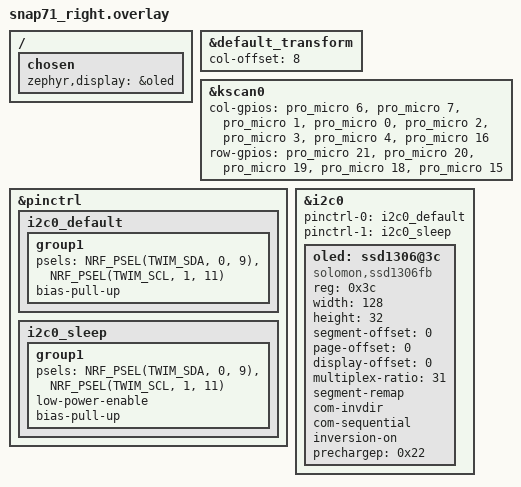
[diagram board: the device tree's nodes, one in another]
#include "snap71.dtsi"

/ {
    chosen {
    zephyr,display = &oled;
    };
};
&default_transform {
    // Set this to the number of columns on the left side.
    col-offset = <8>;
};

&kscan0 {
    // Replace these comments with the GPIO pins in the matrix for the right side.
    // See https://zmk.dev/docs/development/hardware-integration/new-shield#shield-overlays
    col-gpios
        = <&pro_micro 6 GPIO_ACTIVE_HIGH>
        , <&pro_micro 7 GPIO_ACTIVE_HIGH>
        , <&pro_micro 1 GPIO_ACTIVE_HIGH>
        , <&pro_micro 0 GPIO_ACTIVE_HIGH>
        , <&pro_micro 2 GPIO_ACTIVE_HIGH>
        , <&pro_micro 3 GPIO_ACTIVE_HIGH>
        , <&pro_micro 4 GPIO_ACTIVE_HIGH>
        , <&pro_micro 16 GPIO_ACTIVE_HIGH>
        ;
    row-gpios
        = <&pro_micro 21 (GPIO_ACTIVE_HIGH | GPIO_PULL_DOWN)>
        , <&pro_micro 20 (GPIO_ACTIVE_HIGH | GPIO_PULL_DOWN)>
        , <&pro_micro 19 (GPIO_ACTIVE_HIGH | GPIO_PULL_DOWN)>
        , <&pro_micro 18 (GPIO_ACTIVE_HIGH | GPIO_PULL_DOWN)>
        , <&pro_micro 15 (GPIO_ACTIVE_HIGH | GPIO_PULL_DOWN)>
        ;
};

&pinctrl {
    i2c0_default: i2c0_default {
        group1 {
            psels = <NRF_PSEL(TWIM_SDA, 0, 9)>,  /* Pro Micro Pin 7 / D7 -> P1.06 */
                    <NRF_PSEL(TWIM_SCL, 1, 11)>;   /* Pro Micro Pin 9 / D9 -> P0.11 */
                    bias-pull-up;  /* Add this - I2C needs pull-ups */
        };
    };

    i2c0_sleep: i2c0_sleep {
        group1 {
            psels = <NRF_PSEL(TWIM_SDA, 0, 9)>,
                    <NRF_PSEL(TWIM_SCL, 1, 11)>;
            low-power-enable;                     /* Saves battery during low-power modes */
            bias-pull-up;  /* Add this - I2C needs pull-ups */
        };
    };
};

// &pro_micro_i2c {
&i2c0 {
    status = "okay";
    pinctrl-0 = <&i2c0_default>;
    pinctrl-1 = <&i2c0_sleep>;
    pinctrl-names = "default", "sleep";

    /* This embeds the OLED hardware parameters on the same pins */
    oled: ssd1306@3c {
       compatible = "solomon,ssd1306fb";
        reg = <0x3c>;
        width = <128>;
        height = <32>;
        segment-offset = <0>;
        page-offset = <0>;
        display-offset = <0>;
        multiplex-ratio = <31>;
        segment-remap;
        com-invdir;
        com-sequential;
        inversion-on;
        prechargep = <0x22>;
    };
};
